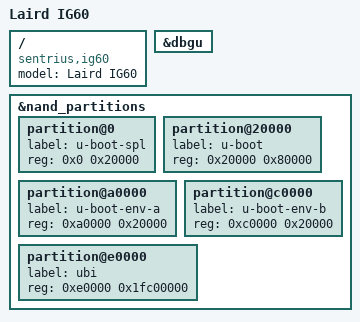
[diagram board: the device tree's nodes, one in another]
// SPDX-License-Identifier: LicenseRef-Ezurio-Clause
/*
 * at91-ig60.dts - Device Tree file for IG60, based on SOM60x2 module
 *
 * Copyright (C) 2018 Ezurio
 */

/dts-v1/;

#include "at91-som60_common.dtsi"
#include "at91-ig60.dtsi"

/ {
	model = "Laird IG60";
	compatible = "sentrius,ig60", "summit,som60", "atmel,sama5d36", "atmel,sama5d3", "atmel,sama5";
};

&dbgu {
	status = "okay";
};

&nand_partitions {
	partition@0 {
		label = "u-boot-spl";
		reg = <0x0 0x20000>;
	};

	partition@20000 {
		label = "u-boot";
		reg = <0x20000 0x80000>;
	};

	partition@a0000 {
		label = "u-boot-env-a";
		reg = <0xa0000 0x20000>;
	};

	partition@c0000 {
		label = "u-boot-env-b";
		reg = <0xc0000 0x20000>;
	};

	partition@e0000 {
		label = "ubi";
		reg = <0xe0000 0x1fc00000>;
	};
};
